# GD32F20x_CL register map
File version: 1.0
CPU: CM3 r2p1, little endian, no MPU, no FPU, 4 interrupt priority bits
Registers are 32-bit, read-write, reset 0x0 unless marked. A register's access mark holds for its fields unless they carry their own. Offsets are from the block's base; [hi:lo] are bit positions; {n}, {i} and the like mark numbered series.

## AFIO — Alternate-function I/Os
Base 0x40010000
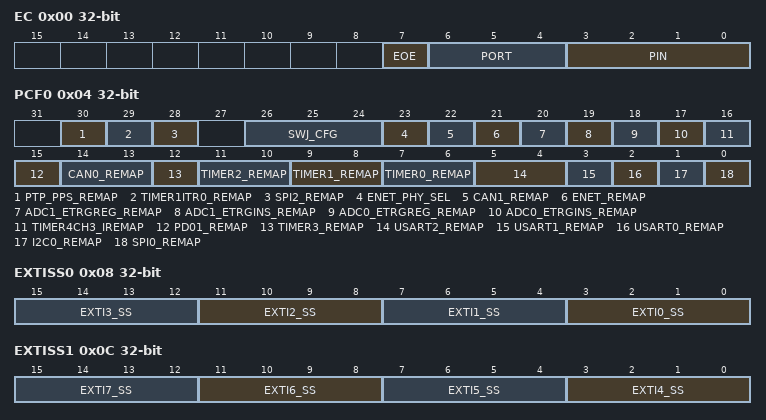
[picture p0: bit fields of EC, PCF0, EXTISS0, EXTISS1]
0x00 EC — Event control register
  [7] EOE — Event output enable
  [6:4] PORT — Event output port selection
  [3:0] PIN — Event output pin selection
0x04 PCF0 — AFIO port configuration register 0
  [30] PTP_PPS_REMAP — Ethernet PTP PPS remapping
  [29] TIMER1ITR0_REMAP — TIMER1 internal trigger 0 remapping
  [28] SPI2_REMAP — SPI2/I2S2 remapping
  [26:24] SWJ_CFG — Serial wire JTAG configuration
  [23] ENET_PHY_SEL — Ethernet MII or RMII PHY selection
  [22] CAN1_REMAP — CAN1 I/O remapping
  [21] ENET_REMAP — Ethernet MAC I/O remapping
  [20] ADC1_ETRGREG_REMAP — ADC 1 external trigger regular conversion remapping
  [19] ADC1_ETRGINS_REMAP — ADC 1 external trigger inserted conversion remapping
  [18] ADC0_ETRGREG_REMAP — ADC 0 external trigger regular conversion remapping
  [17] ADC0_ETRGINS_REMAP — ADC 0 external trigger inserted conversion remapping
  [16] TIMER4CH3_IREMAP — TIMER4 channel3 internal remapping
  [15] PD01_REMAP — Port D0/Port D1 mapping on OSC_IN/OSC_OUT
  [14:13] CAN0_REMAP — CAN0 alternate interface remapping
  [12] TIMER3_REMAP — TIMER3 remapping
  [11:10] TIMER2_REMAP — TIMER2 remapping
  [9:8] TIMER1_REMAP — TIMER1 remapping
  [7:6] TIMER0_REMAP — TIMER0 remapping
  [5:4] USART2_REMAP — USART2 remapping
  [3] USART1_REMAP — USART1 remapping
  [2] USART0_REMAP — USART0 remapping
  [1] I2C0_REMAP — I2C0 remapping
  [0] SPI0_REMAP — SPI0 remapping
0x08 EXTISS0 — EXTI sources selection register 0
  [4n+3:4n] EXTI{n}_SS (n=0..3) — EXTI {n} sources selection
0x0C EXTISS1 — EXTI sources selection register 1
  [4n-13:4n-16] EXTI{n}_SS (n=4..7) — EXTI {n} sources selection
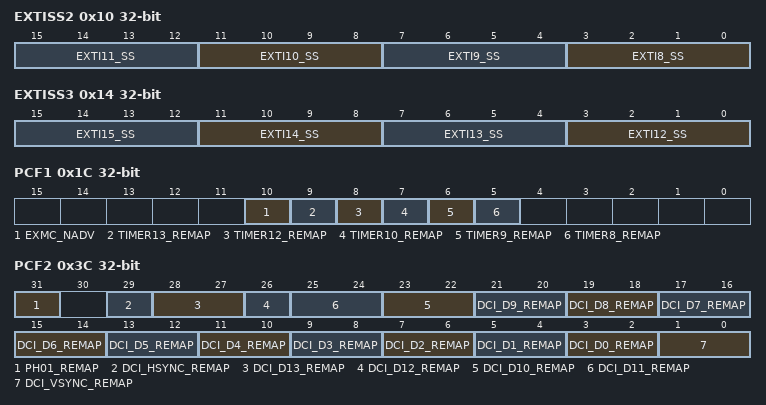
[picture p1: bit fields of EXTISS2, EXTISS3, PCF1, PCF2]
0x10 EXTISS2 — EXTI sources selection register 2
  [4n-29:4n-32] EXTI{n}_SS (n=8..11) — EXTI {n} sources selection
0x14 EXTISS3 — EXTI sources selection register 3
  [4n-45:4n-48] EXTI{n}_SS (n=12..15) — EXTI {n} sources selection
0x1C PCF1 — AFIO port configuration register 1
  [10] EXMC_NADV — EXMC_NADV connect/disconnect
  [9] TIMER13_REMAP — TIMER13 remapping
  [8] TIMER12_REMAP — TIMER12 remapping
  [7] TIMER10_REMAP — TIMER10 remapping
  [6] TIMER9_REMAP — TIMER9 remapping
  [5] TIMER8_REMAP — TIMER8 remapping
0x3C PCF2 — AFIO port configuration register 2
  [31] PH01_REMAP — PH0/PH1 remapping
  [29] DCI_HSYNC_REMAP — DCI_HSYNC remapping
  [28:27] DCI_D13_REMAP — DCI_D13 remapping
  [26] DCI_D12_REMAP — DCI_D12 remapping
  [2n+3:2n+2] DCI_D{n}_REMAP (n=0..11) — DCI_D{n} remapping
  [1:0] DCI_VSYNC_REMAP — DCI_VSYNC remapping
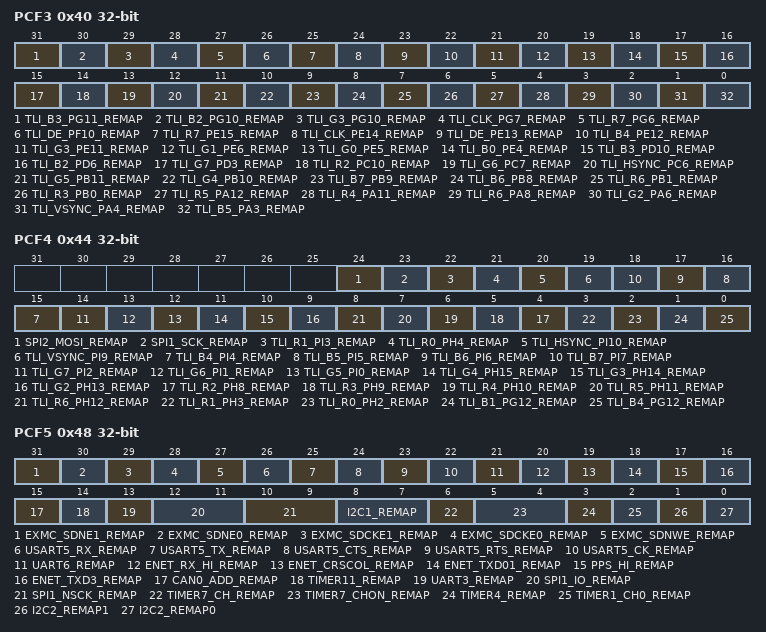
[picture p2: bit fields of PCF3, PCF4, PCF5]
0x40 PCF3 — AFIO port configuration register 3
  [31] TLI_B3_PG11_REMAP — TLI_B3_PG11 remapping
  [30] TLI_B2_PG10_REMAP — TLI_B2_PG10 remapping
  [29] TLI_G3_PG10_REMAP — TLI_G3_PG10 remapping
  [28] TLI_CLK_PG7_REMAP — TLI_CLK_PG7 remapping
  [27] TLI_R7_PG6_REMAP — TLI_R7_PG6 remapping
  [26] TLI_DE_PF10_REMAP — TLI_DE_PF10 remapping
  [25] TLI_R7_PE15_REMAP — TLI_R7_PE15 remapping
  [24] TLI_CLK_PE14_REMAP — TLI_CLK_PE14 remapping
  [23] TLI_DE_PE13_REMAP — TLI_DE_PE13 remapping
  [22] TLI_B4_PE12_REMAP — TLI_B4_PE12 remapping
  [21] TLI_G3_PE11_REMAP — TLI_G3_PE11 remapping
  [20] TLI_G1_PE6_REMAP — TLI_G1_PE6 remapping
  [19] TLI_G0_PE5_REMAP — TLI_G0_PE5 remapping
  [18] TLI_B0_PE4_REMAP — TLI_B0_PE4 remapping
  [17] TLI_B3_PD10_REMAP — TLI_B3_PD10 remapping
  [16] TLI_B2_PD6_REMAP — TLI_B2_PD6 remapping
  [15] TLI_G7_PD3_REMAP — TLI_G7_PD3 remapping
  [14] TLI_R2_PC10_REMAP — TLI_R2_PC10 remapping
  [13] TLI_G6_PC7_REMAP — TLI_G6_PC7 remapping
  [12] TLI_HSYNC_PC6_REMAP — TLI_HSYNC_PC6 remapping
  [11] TLI_G5_PB11_REMAP — TLI_G5_PB11 remapping
  [10] TLI_G4_PB10_REMAP — TLI_G4_PB10 remapping
  [9] TLI_B7_PB9_REMAP — TLI_B7_PB9 remapping
  [8] TLI_B6_PB8_REMAP — TLI_B6_PB8 remapping
  [7] TLI_R6_PB1_REMAP — TLI_R6_PB1 remapping
  [6] TLI_R3_PB0_REMAP — TLI_R3_PB0 remapping
  [5] TLI_R5_PA12_REMAP — TLI_R5_PA12 remapping
  [4] TLI_R4_PA11_REMAP — TLI_R4_PA11 remapping
  [3] TLI_R6_PA8_REMAP — TLI_R6_PA8 remapping
  [2] TLI_G2_PA6_REMAP — TLI_G2_PA6 remapping
  [1] TLI_VSYNC_PA4_REMAP — TLI_VSYNC_PA4 remapping
  [0] TLI_B5_PA3_REMAP — TLI_B5_PA3 remapping
0x44 PCF4 — AFIO port configuration register 4
  [24] SPI2_MOSI_REMAP — SPI2_MOSI remapping
  [23] SPI1_SCK_REMAP — SPI1_SCK remapping
  [22] TLI_R1_PI3_REMAP — TLI_R1_PI3 remapping
  [21] TLI_R0_PH4_REMAP — TLI_R0_PH4 remapping
  [20] TLI_HSYNC_PI10_REMAP — TLI_HSYNC_PI10 remapping
  [19] TLI_VSYNC_PI9_REMAP — TLI_VSYNC_PI9 remapping
  [n+11] TLI_B{n}_PI{n}_REMAP (n=4..7) — TLI_B{n}_PI{n} remapping
  [14] TLI_G7_PI2_REMAP — TLI_G7_PI2 remapping
  [13] TLI_G6_PI1_REMAP — TLI_G6_PI1 remapping
  [12] TLI_G5_PI0_REMAP — TLI_G5_PI0 remapping
  [11] TLI_G4_PH15_REMAP — TLI_G4_PH15 remapping
  [10] TLI_G3_PH14_REMAP — TLI_G3_PH14 remapping
  [9] TLI_G2_PH13_REMAP — TLI_G2_PH13 remapping
  [n+2] TLI_R{n}_PH{n+6}_REMAP (n=2..6) — TLI_R{n}_PH{n+6} remapping
  [3] TLI_R1_PH3_REMAP — TLI_R1_PH3 remapping
  [2] TLI_R0_PH2_REMAP — TLI_R0_PH2 remapping
  [1] TLI_B1_PG12_REMAP — TLI_B1_PG12 remapping
  [0] TLI_B4_PG12_REMAP — TLI_B4_PG12 remapping
0x48 PCF5 — AFIO port configuration register 5
  [31] EXMC_SDNE1_REMAP — EXMC_SDNE1 remapping
  [30] EXMC_SDNE0_REMAP — EXMC_SDNE0 remapping
  [29] EXMC_SDCKE1_REMAP — EXMC_SDCKE1 remapping
  [28] EXMC_SDCKE0_REMAP — EXMC_SDCKE0 remapping
  [27] EXMC_SDNWE_REMAP — EXMC_SDNWE remapping
  [26] USART5_RX_REMAP — USART5_RX remapping
  [25] USART5_TX_REMAP — USART5_TX remapping
  [24] USART5_CTS_REMAP — USART5_CTS remapping
  [23] USART5_RTS_REMAP — USART5_RTS remapping
  [22] USART5_CK_REMAP — USART5_CK remapping
  [21] UART6_REMAP — UART6 remapping
  [20] ENET_RX_HI_REMAP — ENET _RX_HI remapping
  [19] ENET_CRSCOL_REMAP — ENET_CRSCOL remapping
  [18] ENET_TXD01_REMAP — ENET_TXD01 remapping
  [17] PPS_HI_REMAP — PPS_HI remapping
  [16] ENET_TXD3_REMAP — ENET _TXD3 remapping
  [15] CAN0_ADD_REMAP — CAN0_ADD remapping
  [14] TIMER11_REMAP — TIMER11 remapping
  [13] UART3_REMAP — UART3 remapping
  [12:11] SPI1_IO_REMAP — SPI1_IO remapping
  [10:9] SPI1_NSCK_REMAP — SPI1_NSCK remapping
  [8:7] I2C1_REMAP — I2C1 remapping
  [6] TIMER7_CH_REMAP — TIMER7_CH remapping
  [5:4] TIMER7_CHON_REMAP — TIMER7_CHON remapping
  [3] TIMER4_REMAP — TIMER4 remapping
  [2] TIMER1_CH0_REMAP — TIMER1_CH0 remapping
  [1] I2C2_REMAP1 — I2C2 remapping 1
  [0] I2C2_REMAP0 — I2C2 remapping 0
